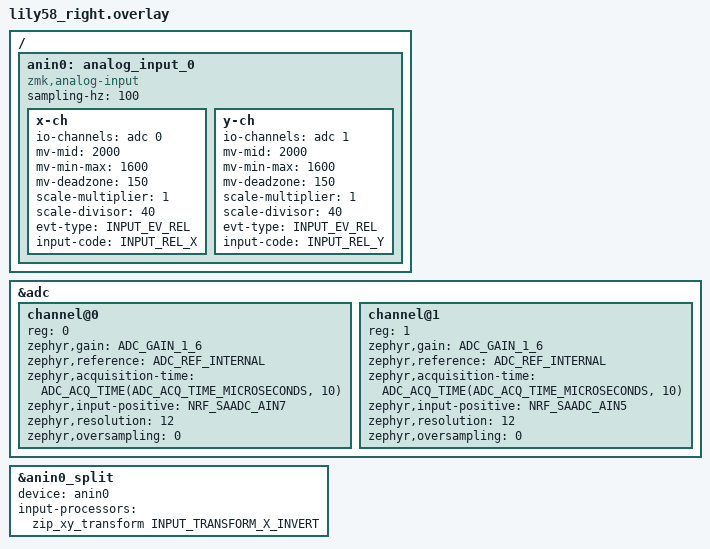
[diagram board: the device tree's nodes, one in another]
#include "lily58.dtsi"
#include <zephyr/dt-bindings/input/input-event-codes.h>
#include <dt-bindings/zmk/input_transform.h>
#include <input/processors.dtsi>

&adc {
    status = "okay";
    #address-cells = <1>;
    #size-cells = <0>;

    channel@0 {
        reg = <0>;
        zephyr,gain = "ADC_GAIN_1_6";
        zephyr,reference = "ADC_REF_INTERNAL";
        zephyr,acquisition-time = <ADC_ACQ_TIME(ADC_ACQ_TIME_MICROSECONDS, 10)>;
        zephyr,input-positive = <NRF_SAADC_AIN7>;     /* P0.31 */
        zephyr,resolution = <12>;
        zephyr,oversampling = <0>;
    };

    channel@1 {
        reg = <1>;
        zephyr,gain = "ADC_GAIN_1_6";
        zephyr,reference = "ADC_REF_INTERNAL";
        zephyr,acquisition-time = <ADC_ACQ_TIME(ADC_ACQ_TIME_MICROSECONDS, 10)>;
        zephyr,input-positive = <NRF_SAADC_AIN5>;     /* P0.29 */
        zephyr,resolution = <12>;
        zephyr,oversampling = <0>;
    };
};

/ {
    anin0: analog_input_0 {
        compatible = "zmk,analog-input";
        sampling-hz = <100>;

        x-ch {
            io-channels = <&adc 0>;
            mv-mid = <2000>;
            mv-min-max = <1600>;
            mv-deadzone = <150>;
            scale-multiplier = <1>;
            scale-divisor = <40>;
            evt-type = <INPUT_EV_REL>;
            input-code = <INPUT_REL_X>;
        };

        y-ch {
            io-channels = <&adc 1>;
            mv-mid = <2000>;
            mv-min-max = <1600>;
            mv-deadzone = <150>;
            scale-multiplier = <1>;
            scale-divisor = <40>;
            evt-type = <INPUT_EV_REL>;
            input-code = <INPUT_REL_Y>;
        };
    };
};

&anin0_split {
    device = <&anin0>;
    input-processors = <&zip_xy_transform INPUT_TRANSFORM_X_INVERT>;
};
